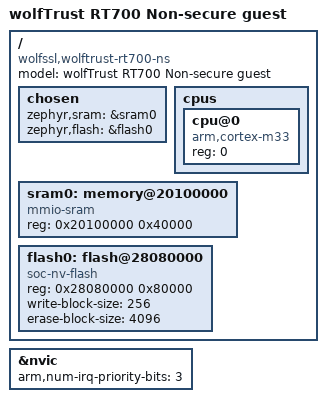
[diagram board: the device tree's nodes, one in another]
/dts-v1/;
#include <arm/armv8-m.dtsi>
/ {
    model = "wolfTrust RT700 Non-secure guest";
    compatible = "wolfssl,wolftrust-rt700-ns";
    chosen {
        zephyr,sram = &sram0;
        zephyr,flash = &flash0;
    };
    cpus {
        #address-cells = <1>;
        #size-cells = <0>;
        cpu@0 {
            device_type = "cpu";
            compatible = "arm,cortex-m33";
            reg = <0>;
        };
    };
    sram0: memory@20100000 {
        compatible = "mmio-sram";
        reg = <0x20100000 0x40000>;
    };
    flash0: flash@28080000 {
        compatible = "soc-nv-flash";
        reg = <0x28080000 0x80000>;
        write-block-size = <256>;
        erase-block-size = <4096>;
    };
};
&nvic { arm,num-irq-priority-bits = <3>; };
